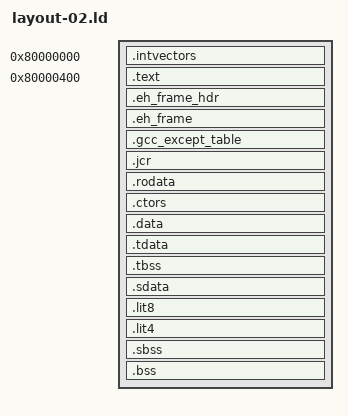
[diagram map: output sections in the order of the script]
/* ========================================================================
 *
 * n64.ld -- Libdragon linker script
 *
 * Originally based on n64ld.x, developed by Frank Somers <frank@g0dev.com>,
 * with modifications by hcs (halleyscometsoftware@hotmail.com),
 * released under the Unlicense.
 * ========================================================================
 */

OUTPUT_FORMAT ("elf32-bigmips", "elf32-bigmips", "elf32-littlemips")
OUTPUT_ARCH (mips)
EXTERN (_start)
ENTRY (_start)

PHDRS
{
    irq PT_LOAD AT ( 0x80000000 );
    main PT_LOAD AT ( 0x80000400 );
}

SECTIONS {
    .intvectors 0x80000000 : {
        . = ALIGN(32);
        KEEP(*(.intvectors))
        __intvectors_end = .;
    } :irq

    /* The text section carries the app code and its relocation addr is
    * the first byte of the cart domain in cached, unmapped memory
    */
    .text 0x80000400 : {
        __text_start = .;
        *(.boot)
        . = ALIGN(16);
        *(.text)
        /* MipsFit: verified unique input sections; GC remains enabled */
        *(.text.sinf_approx)
        *(.text.fm_sincosf)
        *(.text._ZN3e645water6updateEf)
        *(.text._ZN3e6410angle_wrapEf)
        *(.text._ZN3e646player21setCharacter3DControlENS_8PlayerIDEPNS_8ViewportE)
        *(.text._exit)
        *(.text.audio_get_num_buffers)
        *(.text._ZN3e644game5state6updateEv)
        *(.text._ZN3e644mesh6deform6updateEPKPNS_8Entity3DEhh)
        *(.text.rdpq_mode_fog)
        *(.text._ZN3e649collision15dynamicAABBTree9queryAABBEPKNS_15DynamicAABBTreeEPvPFiS5_lENS_4AABBE)
        *(.text.t3d_skeleton_update)
        *(.text.t3d_mat4_to_fixed)
        *(.text.t3d_tri_draw_strip)
        *(.text.t3d_mat4_from_srt)
        *(.text._ZN3e6410quaternion12rotateVectorEPKNS_10QuaternionEPKNS_7Vector3E)
        *(.text._ZN3e648skeleton11getBonePoseEPK11T3DSkeletonsP9fm_vec3_tP9fm_quat_t)
        *(.text.rdpq_text_vprintf)
        *(.text._ZN3e643box7raycastEPKNS_3BoxEPKNS_9TransformEPNS_11RaycastDataE)
        *(.text._ZN3e647matrix37productEPKNS_7Matrix3ES3_)
        *(.text._ZN3e647matrix315transformVectorEPKNS_7Matrix3EPKNS_7Vector3E)
        *(.text._ZN3e649transform19mulVectorTransposedEPKNS_9TransformEPKNS_7Vector3E)
        *(.text._ZN3e647stage2d6createEPKNS0_3DefEPNS_8Entity2DE)
        *(.text._ZN3e649transform9mulVectorEPKNS_9TransformEPKNS_7Vector3E)
        *(.text._ZN9gameStateL15controlGameplayEv)
        *(.text._ZN3e644mesh4cullEPNS_4MeshEPK11T3DViewport)
        *(.text.__rdpq_fixup_write8_syncchange)
        *(.text.bvh_query_node)
        *(.text.t3d_model_bvh_query_frustum)
        *(.text.t3d_mat4_from_srt_euler)
        *(.text.t3d_anim_update)
        *(.text.joybus_get_identifier)
        *(.text._ZN3e647contact6solver10initializeEPNS_7Contact6SolverEPNS_7physics6IslandE)
        *(.text.t3d_mat4_to_fixed_3x4)
        *(.text.t3d_mat4fp_from_srt)
        *(.text._ZN3e647scene3d14updateEntitiesEh)
        *(.text.__rdpq_mode_change_som)
        *(.text._ZN3e647scene3d16setRenderContextEPKNS_7Scene3DEPNS_6Render7ContextEPKNS_8ViewportE)
        *(.text._ZN3e644aabb8overlapsEPKNS_4AABBES3_)
        *(.text.__rdpq_set_mode_fill)
        *(.text._ZN3e647contact7manager15findNewContactsEPNS_7Contact7ManagerE)
        *(.text._ZN3e6411character3dL14weaponModifierEP11T3DSkeletonPv)
        *(.text.t3d_quat_nlerp)
        *(.text.fm_sinf)
        *(.text._ZN3e649particles6updateEh)
        *(.text.__rdpq_block_run_no_rdp)
        *(.text.__vi_interrupt)
        *(.text._ZN3e647capsule11computeAABBEPKNS_7CapsuleEPKNS_9TransformEPNS_4AABBE)
        *(.text._ZN3e647matrix312outerProductEPKNS_7Vector3ES3_)
        *(.text._ZN3e648viewport6attachEv)
        *(.text.joypad_get_buttons_held)
        *(.text._ZN3e6411character2d8movementL10setRollingEPNS_11Character2DEPNS0_15MovementCommandEf)
        *(.text._ZN3e649particles4drawEv)
        *(.text._ZN3e644mesh4part9setOffsetEPNS_4MeshEhPKNS_6Render9TransformE)
        *(.text.t3d_matrix_push)
        *(.text.t3d_matrix_stack)
        *(.text.rdpq_text_printf)
        *(.text.vi_write_masked)
        *(.text._ZN3e644mesh17setMatrixFromBodyEPNS_4MeshEPKNS_7Vector3EPKNS_10QuaternionES5_h)
        *(.text.rspq_block_run)
        *(.text._ZN3e649rigidBody7isAwakeEPKNS_9RigidBodyE)
        *(.text._ZN3e646renderL11runElementsEPKNS_6Render7ContextEPKttPPK11T3DSkeletonPPK9T3DMat4FP.constprop.0)
        *(.text._ZN3e644menu7control4readEPNS0_8ControlsEPKNS_10ControllerEPKNS0_14ControlBindingE)
        *(.text._ZN3e6411character3d9Animation18setLocomotionSpeedERNS_11Character3DEf)
        *(.text._ZN3e649collision15dynamicAABBTreeL10insertLeafEPNS_15DynamicAABBTreeEl)
        *(.text._ZN3e647contact7manager14testCollisionsEPNS_7Contact7ManagerE)
        *(.text._ZN3e644menu7controlL7getStepENS1_9DirectionEbb)
        *(.text._ZN3e649collision11sphereToBoxEPNS_7Contact8ManifoldEPNS_7physics5ShapeES6_)
        *(.text._ZN3e649transform7productEPKNS_9TransformES3_)
        *(.text._ZN3e649rigidBody10canCollideEPKNS_9RigidBodyES3_)
        *(.text.__entropy_add)
        *(.text.mixer_ch_play)
        *(.text.t3d_light_set_ambient)
        *(.text.t3d_segment_set)
        *(.text.acct_switch)
        *(.text._ZN3e649collision8boxToBoxEPNS_7Contact8ManifoldEPNS_7physics5ShapeES6_)
        *(.text._ZN3e644mesh4part9getMatrixEPKNS_4MeshEhh)
        *(.text._ZN3e649collision7collideEPNS_7Contact8ManifoldEPNS_7physics5ShapeES6_)
        *(.text._ZN3e648entity3d12setTransformEPNS_8Entity3DEPKNS_11character3d13KinematicBodyE)
        *(.text._ZN3e648camera3d14getAngleAroundEPKNS_6CameraEPKNS_7Vector3E)
        *(.text.rspq_flush_internal)
        *(.text.joypad_vi_interrupt_callback)
        *(.text._ZN3e6410quaternion7productEPKNS_10QuaternionES3_)
        *(.text.joypad_get_axis_values.constprop.0)
        *(.text.rdpq_fence)
        *(.text.joypad_get_inputs)
        *(.text.__rdpq_interrupt)
        *(.text.__rdpq_clear)
        *(.text.t3d_light_set_count)
        *(.text.t3d_vec3_cross)
        *(.text._ZN3e644time6updateEv)
        *(.text._ZN3e644meshL11composePartEPKNS_4MeshEPKNS_6Render9TransformEPNS_7Vector3EPNS_10QuaternionES9_)
        *(.text.rdpq_detach_cb)
        *(.text.timer_update_compare)
        *(.text.mips_disasm)
        *(.text._ZN3e649collision17capsuleToTriangleEPNS_7Contact8ManifoldEPKNS_7CapsuleEPKNS_9TransformEPKNS_8TriangleE)
        *(.text.display_get_fps)
        *(.text._ZN3e648triangle14closestToPointEPKNS_8TriangleEPKNS_7Vector3E)
        *(.text._ZN3e644time5resetEv)
        *(.text.rdpq_mode_antialias)
        *(.text.timer_callback)
        *(.text._ZN3e643box9testPointEPKNS_3BoxEPKNS_9TransformEPKNS_7Vector3E)
        *(.text._ZN3e647matrix325transformVectorTransposedEPKNS_7Matrix3EPKNS_7Vector3E)
        *(.text._ZN3e6411character2d8movementL13setLocomotionEPNS_11Character2DEPNS0_15MovementCommandEf)
        *(.text.display_set_fps_limit)
        *(.text._ZN3e647contact10constraint14solveCollisionEPNS_7Contact10ConstraintE)
        *(.text._ZN3e648camera3d7controlL17setSpringArmInputEPNS_6CameraEff)
        *(.text.t3d_mat4_to_frustum)
        *(.text._ZN3e648camera3d9springArm6updateEPNS_6CameraEPNS_7Vector3Ef)
        *(.text._ZN3e6410controller3getEv)
        *(.text.rspq_flush)
        *(.text.mixer_try_play)
        *(.text.exception_reset_time)
        *(.text.rdpq_paragraph_builder_span)
        *(.text._ZN3e644aabb12containsAABBEPKNS_4AABBES3_)
        *(.text._ZN3e647vector39normalizeEPNS_7Vector3E)
        *(.text.t3d_mat4_mul_vec3)
        *(.text._ZN3e6410controller6isHeldEPKNS_10ControllerENS_8ButtonIDE)
        *(.text._ZL27staminaWheel_setRenderStatePK12StaminaWheel)
        *(.text.si_interrupt)
        *(.text.rdpq_font_load_buf)
        *(.text._ZN3e646render4drawEv)
        *(.text._ZN3e645debug2ui4drawEv)
        *(.text.vi_write_begin)
        *(.text._ZN3e642ui16setRenderContextEPKNS_2UIEPNS_6Render7ContextE)
        *(.text.t3d_matrix_set_proj)
        *(.text._ZSt14get_unexpectedv)
        *(.text.joypad_get_buttons_pressed)
        *(.text._ZN3e649collision15dynamicAABBTree6updateEPNS_15DynamicAABBTreeElNS_4AABBE)
        *(.text._ZN3e647physics5shape9testPointEPKNS0_5ShapeEPKNS_7Vector3E)
        *(.text.display_get_zbuf)
        *(.text._ZN3e648viewport8getScaleEv)
        *(.text._ZN3e643fog3getEv)
        *(.text.__rdpq_write8_syncchange)
        *(.text.__rdpq_fill_rectangle)
        *(.text.t3d_viewport_set_projection)
        *(.text._ZN3e644time4initEv)
        *(.text.__TI_handler)
        *(.text.audio_get_queued_buffers)
        *(.text.t3d_dmem_set_u16)
        *(.text.rewind_anim)
        *(.text.t3d_dmem_set_u32)
        *(.text._ZN3e643fog3setEPNS_3FogE)
        *(.text._ZN3e6410controller10isReleasedEPKNS_10ControllerENS_8ButtonIDE)
        *(.text.rdpq_detach_show)
        *(.text._ZN3e644mesh8material10isDeferredEh)
        *(.text.fm_cosf)
        *(.text._ZN3e645sound4pollEv)
        *(.text._ZN3e649collision15dynamicAABBTree11getUserDataEPKNS_15DynamicAABBTreeEl)
        *(.text._ZN3e644game7runStepEv)
        *(.text.vi_write_idx_masked)
        *(.text.rdpq_mode_filter)
        *(.text._ZN3e649transform17productTransposedEPKNS_9TransformES3_)
        *(.text.waveform_vadpcm_read_compressed.isra.0)
        *(.text._ZN3e6410quaternion9toMatrix3EPKNS_10QuaternionE)
        *(.text.joypad_read_async.part.0)
        *(.text.display_show)
        *(.text._ZN3e647scene2d3getEv)
        *(.text._ZN3e644mesh6deform9bindFrameEPNS_4MeshEh)
        *(.text.audio_callback.part.0)
        *(.text.vi_show)
        *(.text.rdpq_set_mode_standard)
        *(.text.__vblank_interrupt)
        *(.text._ZN3e646memory5stack8allocateEPNS0_5StackEl)
        *(.text._ZN3e6410controller18getStickNormalizedEPKNS_10ControllerE)
        *(.text.joybus_exec_async)
        *(.text.enable_interrupts)
        *(.text.audio_get_buffer_length)
        *(.text.display_try_get)
        *(.text._ZN3e647matrix37inverseEPKNS_7Matrix3E)
        *(.text._ZN3e649rigidBody18synchronizeProxiesEPNS_9RigidBodyE)
        *(.text._ZN3e647physics5shape11computeAABBEPKNS0_5ShapeEPNS_4AABBE)
        *(.text.vi_write_end)
        *(.text.joypad_get_buttons_released)
        *(.text._ZN3e6416ease_quad_in_outEf)
        *(.text._ZN3e649animation13syncGridClipsEPNS_9AnimationEPKNS1_4NodeEff)
        *(.text._ZN3e649animation12getGridClipsEPKNS_9Animation4NodeEffPh)
        *(.text._ZN3e6412ease_expo_inEf)
        *(.text._ZN3e649collision10broadPhase6updateEPNS_10BroadPhaseElNS_4AABBE)
        *(.text._ZN3e645light3setEPKNS0_3DefE)
        *(.text._ZN3e6410quaternion9fromEulerEfff)
        *(.text._ZN3e6411character3d7physicsL15collectTriangleEPvl)
        *(.text._ZN3e648camera3d7control6updateEPNS_6CameraEPKNS0_14ControlBindingEPKNS_7Scene3DEf)
        *(.text.rdpq_sync_full)
        *(.text._ZN3e6411character3d9Animation13getTurningAvgEPKNS0_17AnimationSettingsEff)
        *(.text.t3d_screen_clear_depth)
        *(.text.attach)
        *(.text._ZN3e6411character3d9Animation12getGaitParamEfPKNS0_16MovementSettingsE)
        *(.text.audio_callback)
        *(.text._ZN3e644game3getEv)
        *(.text._ZN3e649collision10broadPhase11testOverlapEPKNS_10BroadPhaseEll)
        *(.text._ZN3e642ui3getEv)
        *(.text._ZN3e644mesh9setMatrixEPNS_4MeshEPKNS_6Render9TransformEh)
        *(.text.__mixer_round_wait)
        *(.text.texload_recalc_tileparms)
        *(.text.rdpq_text_get_font)
        *(.text.__rdpq_texture_rectangle_offline)
        *(.text.__rdpq_texture_rectangle)
        *(.text.rdpq_font_render_paragraph)
        *(.text.mixer_channel_volumes)
        *(.text._ZN3e6410controllerL10readButtonEPK16joypad_buttons_uNS_8ButtonIDE)
        *(.text.__MI_handler)
        *(.text.data_cache_hit_writeback)
        *(.text._ZN3e647physics6island7addBodyEPNS0_6IslandEPNS_9RigidBodyE)
        *(.text._ZN3e647scene3d16updateCharactersEh)
        *(.text.__retarget_lock_release_recursive)
        *(.text.__rdpq_set_fill_color)
        *(.text.t3d_viewport_look_at)
        *(.text._ZN3e644meshL11writeMatrixEP9T3DMat4FPPKNS_7Vector3EPKNS_10QuaternionES5_)
        *(.text.__rdpq_write8)
        *(.text.joypad_is_connected)
        *(.text.t3d_viewport_set_perspective)
        *(.text._ZN3e6411character2d7physics7collideEPNS_11Character2DE)
        *(.text.joypad_accessory_polled)
        *(.text.startup.__ktls_constructor)
        *(.text._ZN3e646renderL13scrollTextureEPK11T3DMaterialPKNS_7Vector2E)
        *(.text.data_cache_hit_invalidate)
        *(.text._ZN3e649animation7getClipEPNS_9AnimationEh)
        *(.text.rdpq_paragraph_render)
        *(.text._ZN3e647scene3d3getEv)
        *(.text.joypad_detect_callback)
        *(.text._ZN3e6411uiAnimation6player6updateEPNS_11UIAnimation6PlayerEPNS_2UIEf)
        *(.text._ZN3e647scene3d10getPhysicsEv)
        *(.text.__rdpq_fill_rectangle_offline)
        *(.text._ZN3e6410controller19getCStickNormalizedEPKNS_10ControllerE)
        *(.text.__rdpq_fixup_mode3)
        *(.text.decompress_aplib_partial.part.0)
        *(.text.__rdpq_reset_render_mode)
        *(.text._ZN3e647vector312computeBasisEPKNS_7Vector3EPS1_S4_)
        *(.text.kirq_begin_wait_vi)
        *(.text.fm_expf)
        *(.text.get_ticks)
        *(.text.__rdpq_autosync_change)
        *(.text.t3d_vec3_norm)
        *(.text.rdpq_mode_end)
        *(.text.rdpq_mode_push)
        *(.text._ZN3e642ui6updateEPKNS_11UIAnimationE)
        *(.text._ZN3e649rigidBody12getTransformEPKNS_9RigidBodyE)
        *(.text._ZN3e649rigidBody17setLinearVelocityEPNS_9RigidBodyENS_7Vector3E)
        *(.text.mixer_ch_alloc)
        *(.text._ZN3e6411character3d9Animation18setLocomotionParamERNS_11Character3DEf)
        *(.text._ZN3e649animation12blendSegmentEfhPf)
        *(.text.rspq_highpri_end)
        *(.text.__rsp_crash)
        *(.text.t3d_mat4_look_at)
        *(.text._ZN3e6424segment_closestToSegmentEPKNS_7Vector3ES2_S2_S2_PS0_S3_)
        *(.text.rdpq_mode_persp)
        *(.text.__rdpq_fixup_mode4)
        *(.text._ZN3e647contact6solver8shutdownEPNS_7Contact6SolverE)
        *(.text.joybus_msg_send)
        *(.text.rdpq_text_printn)
        *(.text._ZN3e647physics4stepEPNS0_5WorldE)
        *(.text._ZN3e644aabb14closestToPointEPKNS_4AABBEPKNS_7Vector3E)
        *(.text._ZN3e645light3getEv)
        *(.text._ZN3e649collision15dynamicAABBTree10getFatAABBEPKNS_15DynamicAABBTreeEl)
        *(.text._ZN3e6411character3d8movementL13setLocomotionEPNS_11Character3DEPNS0_15MovementCommandEf)
        *(.text._ZN3e647capsule10getSegmentEPKNS_7CapsuleEPKNS_9TransformEPNS_7Vector3ES8_)
        *(.text._ZN3e649rigidBody23setTransformPositionYawEPNS_9RigidBodyENS_7Vector3Ef)
        *(.text._ZN3e6412meshCollider9queryAABBEPKNS_12MeshColliderEPvPFiS4_lENS_4AABBE)
        *(.text._ZN3e649collision10broadPhase11updatePairsEPNS_10BroadPhaseE)
        *(.text._ZN3e649collision22capsuleToStaticCapsuleEPNS_7Contact8ManifoldEPKNS_7CapsuleEPKNS_9TransformES6_S9_)
        *(.text._ZN3e648entity3d17setMatrixFromBodyEPNS_8Entity3DEh)
        *(.text._ZN3e646memory5stack4freeEPNS0_5StackEPv)
        *(.text._ZN3e6410quaternion11toAxisAngleEPKNS_10QuaternionEPNS_7Vector3EPf)
        *(.text._ZN3e6411character3d9Animation11getGaitAxisERKNS_11Character3DEf)
        *(.text._ZN3e6411character3d9Animation9setParamsERNS_11Character3DEf)
        *(.text._ZN3e649animation14setActiveNodesEPNS_9AnimationE)
        *(.text._ZN3e6411character3d9Animation13setJumpParamsERNS_11Character3DEf)
        *(.text._ZN3e645waterL6scrollEPNS_7Vector2EPKfff)
        *(.text.display_get)
        *(.text._ZN3e6411character3d9Animation21setStrafeLockedParamsERNS_11Character3DEf)
        *(.text.display_get_width)
        *(.text._ZN3e6411character3d9Animation12setRollParamERNS_11Character3DEf)
        *(.text.joypad_poll.part.0)
        *(.text._ZN3e6411character3d9Animation19setJumpFootingSpeedERNS_11Character3DE)
        *(.text._ZN3e6411character3d9Animation13setSwimParamsERNS_11Character3DEf)
        *(.text._ZL21staminaWheel_setInputPN3e648ParticleEh)
        *(.text.__rdpq_fixup_mode)
        *(.text.__rdpq_set_color_image)
        *(.text.rdpq_attach)
        *(.text.t3d_mat4_perspective)
        *(.text.joypad_inputs_from_n64_controller_read)
        *(.text.rdpq_set_z_image)
        *(.text.decompress_shrinkler_read)
        *(.text.__retarget_lock_acquire_recursive)
        *(.text._ZN3e6411character3d9Animation15setStrafeParamsERNS_11Character3DEf)
        *(.text._ZN3e649propSound6updateEPNS_7physics5WorldE)
        *(.text.t3d_light_set_point)
        *(.text.internal_open)
        *(.text._ZN3e647physics6island5solveEPNS0_6IslandE)
        *(.text.audio_write_begin)
        *(.text.fm_atan2f)
        *(.text.__rdpq_set_scissor)
        *(.text._ZN3e646player6updateEv)
        *(.text._ZN3e649rigidBody10setToAwakeEPNS_9RigidBodyE)
        *(.text.disable_interrupts)
        *(.text.texload_block_8bpp)
        *(.text.joypad_read_callback)
        *(.text._ZN3e648viewport5clearE7color_t)
        *(.text.__vi_validate_config)
        *(.text.__display_callback)
        *(.text._ZN3e647matrix36scaledEPKNS_7Matrix3Ef)
        *(.text._ZN3e647contact6solver8preSolveEPNS_7Contact6SolverEf)
        *(.text._ZN3e6411character3d8movement7setModeEPNS0_8MovementEh)
        *(.text._ZN3e6411character3d7control6updateEPNS_11Character3DEPNS0_15MovementCommandEPKNS0_8ControlsEf)
        *(.text._ZN3e6411character3d5sound6updateEPNS_11Character3DE)
        *(.text._ZN3e646memory4heap4initEPNS0_4HeapE)
        *(.text.__rdpq_clear_z_with_rsp)
        *(.text._ZN3e6411character3d6weapon5drawnEPKNS_11Character3DE)
        *(.text._ZN3e6411character3d5stats6updateEPNS_11Character3DEPKNS0_15MovementCommandEf)
        *(.text._ZN3e646player3getEv)
        *(.text._ZN3e645sound6updateEv)
        *(.text.usb_initialize)
        *(.text.rdpq_mode_pop)
        *(.text.t3d_viewport_attach)
        *(.text.t3d_matrix_set)
        *(.text.rdpq_paragraph_builder_font)
        *(.text.audio_write_end)
        *(.text.t3d_matrix_pop)
        *(.text._ZN3e644mesh8material11hasVertexFxEh)
        *(.text._ZN3e648camera3d8getRightEPKNS_6CameraE)
        *(.text._ZN3e647contact6solver5solveEPNS_7Contact6SolverE)
        *(.text.decompress_lz4_read)
        *(.text._ZN3e647physics6updateEPNS0_5WorldEf)
        *(.text._ZN3e6411Character3D14updateMovementEPNS_11character3d15MovementCommandEf)
        *(.text._ZN3e6411character3d8movementL21setHorizontalVelocityEPNS_11Character3DEffff)
        *(.text._ZN3e648viewport6detachEv)
        *(.text.joypad_poll)
        *(.text.rdpq_paragraph_builder_end)
        *(.text._ZN3e644mesh8material5blockEh)
        *(.text.rdpq_mode_dithering)
        *(.text.__rdpq_paragraph_builder_update_bbox_width.part.0)
        *(.text._ZN3e648entity3d9setMatrixEPNS_8Entity3DEh)
        *(.text.rspq_highpri_begin)
        *(.text._ZN3e6411character2d9animation6updateEPNS_11Character2DEf)
        *(.text._ZN9gameStateL14updateGameplayEv)
        *(.text._ZN3e649collision10broadPhase11insertShapeEPNS_10BroadPhaseEPNS_7physics5ShapeENS_4AABBE)
        *(.text.vi_set_origin)
        *(.text._ZN3e6411character3d9Animation10setFootingERNS_11Character3DE)
        *(.text._ZN3e6411character3d7physics7collideEPNS_11Character3DEPKNS_7physics5WorldE)
        *(.text.mixer_poll_async)
        *(.text.mixer_emit_channel)
        *(.text.__rdpq_paragraph_build)
        *(.text.vi_get_refresh_rate)
        *(.text.rdpq_mode_begin)
        *(.text._ZN3e646memory5stack7reserveEPNS0_5StackEm)
        *(.text.kmutex_lock)
        *(.text.rspq_switch_context)
        *(.text.rdpq_paragraph_builder_begin)
        *(.text._ZN3e6411character3d6createEPKNS0_3DefEPNS_8Entity3DE)
        *(.text._ZN3e6411character3d9Animation14setClimbParamsERNS_11Character3DEf)
        *(.text.graphics_draw_box)
        *(.text._ZN3e647vector310normalizedEPKNS_7Vector3E)
        *(.text._ZN3e6411ease_linearEf)
        *(.text._ZN3e6411character3d9Animation15setAimingParamsERNS_11Character3DEf)
        *(.text._ZN3e647scene2d4loadEPKNS0_3DefEPKNS_8controls3DefE)
        *(.text.rdpq_set_color_image)
        *(.text._ZN3e648camera3d6updateEPNS_6CameraEPNS_7Vector3EPKNS_7Scene3DEf)
        *(.text._ZN3e645debug2ui7showFPSEv)
        *(.text.rspq_next_buffer)
        *(.text._ZN3e648viewport5has3DEv)
        *(.text._ZN3e6411character3d7physics8syncBodyEPNS_11Character3DE)
        *(.text._ZN3e646memory4heap8allocateEPNS0_4HeapEl)
        *(.text._ZN3e648buoyancy5applyEPNS_7physics5WorldEPKNS0_6VolumeE)
        *(.text.__rdpq_clear_z)
        *(.text._ZN3e647physics6island10initializeEPNS0_6IslandE)
        *(.text._ZN3e647scene2d16setRenderContextEPKNS_7Scene2DEPNS_6Render7ContextE)
        *(.text._ZN3e6411character3d3aim5applyEP11T3DSkeletonPv)
        *(.text._ZN3e6411character3d7control4readEPNS0_8ControlsEPKNS0_14ControlBindingE)
        *(.text._ZNSt9type_infoD2Ev)
        *(.text.t3d_frustum_vs_aabb_s16)
        *(.text.joybus_identify_callback)
        *(.text._ZN3e6411character3d8movement12isLocomotionEh)
        *(.text._ZN3e648viewport20setPerspectiveCameraEv)
        *(.text._ZN3e6410controller4pollEv)
        *(.text.t3d_mat4_mul)
        *(.text.timer_poll)
        *(.text.__rspq_deferred_poll)
        *(.text.joybus_identify_async.part.0)
        *(.text.inspector_stdout)
        *(.text._ZN3e644meshL12localFrustumEP10T3DFrustumPKS1_PKNS_7Vector3EPKNS_10QuaternionES7_)
        *(.text._ZN3e6410quaternion13fromAxisAngleEPKNS_7Vector3Ef)
        *(.text._ZN3e6411character3d7physicsL19floorProbe_considerEPNS1_10FloorProbeEPKNS_7Vector3EfS6_.isra.0)
        *(.text.mixer_ch_seek)
        *(.text.__cxa_get_globals_fast)
        *(.text._ZN3e648skeleton9modifiers5applyEPNS0_9ModifiersEP11T3DSkeleton)
        *(.text._ZN3e6410controller9isPressedEPKNS_10ControllerENS_8ButtonIDE)
        *(.text.t3d_frame_start)
        *(.text._ZN3e647vector39magnitudeEPKNS_7Vector3E)
        *(.text.startup.main)
        *(.text._ZN3e6411Character3D12setAnimationEv)
        *(.text.__rdpq_font_glyph)
        *(.text._ZN3e64L33springBoneCollision_collideSphereEPKNS_7Vector3EfbffS2_.isra.0)
        *(.text._ZN3e6416springBone_applyEP11T3DSkeletonPv)
        *(.text._ZN3e6410quaternion11fromMatrix3EPKNS_7Matrix3E)
        *(.text._ZN3e649animation8evaluateEPNS_9AnimationEf)
        *(.text.startup.__init_cop1)
        *(.text._ZN3e649animation6buffer11blendLayersEPKNS_9Animation6BufferEPK11T3DSkeleton)
        *(.text._ZN3e649animation14closeIdleClipsEPNS_9AnimationE)
        *(.text._ZNKSt9type_info14__is_pointer_pEv)
        *(.text._ZN3e644time3getEv)
        *(.text.joypad_get_axis_pressed)
        *(.text.__rdpq_block_run_with_rdp)
        *(.text._ZN3e6411character3d6weapon8setBonesEPNS_11Character3DE)
        *(.text._ZN3e649collision15dynamicAABBTree6insertEPNS_15DynamicAABBTreeENS_4AABBEPv)
        *(.text._ZN3e649collision18capsuleToStaticBoxEPNS_7Contact8ManifoldEPKNS_7CapsuleEPKNS_9TransformEPKNS_3BoxES9_)
        *(.text._ZN3e6411character3d7physicsL7recoverEPNS_11Character3DEPKNS_7physics5WorldEPNS1_14CollisionStateE.constprop.0)
        *(.text._ZN3e644aabb16closestToSegmentEPKNS_4AABBEPKNS_7Vector3ES6_)
        *(.text._ZN3e6422segment_closestToPointEPKNS_7Vector3ES2_S2_)
        *(.text.rspq_overlay_register_static)
        *(.text._ZN3e6412meshCollider11getTriangleEPKNS_12MeshColliderElPNS_8TriangleE)
        *(.text._ZN3e6416ease_expo_in_outEf)
        *(.text._ZN3e649particles6buffer6createENS_8Particle4TypeEm)
        *(.text.rdpq_tex_blit)
        *(.text._ZN3e644menu8getIndexEv)
        *(.text._ZN3e647physics5world7setWindEPNS0_5WorldENS_7Vector3E)
        *(.text._ZN3e649collision17fixTriangleNormalEPKNS_8TriangleEPKNS_7Vector3ES6_S6_)
        *(.text.backtrace_foreach.constprop.0)
        *(.text.__mixer_rdram_copy)
        *(.text._ZN3e6411character3d7physicsL13floorDistanceEPKNS_11Character3DEPKNS_7physics5WorldE)
        *(.text.ioctl)
        *(.text._ZN3e649rigidBody8addShapeEPNS_9RigidBodyEPKNS_7physics5Shape3DefENS_7Vector3E)
        *(.text.joybus_detect_now)
        *(.text.tpx_particle_draw_s8)
        *(.text._ZN3e645cloth4stepEPNS_5ClothEf)
        *(.text._ZN3e648viewport3getEv)
        *(.text._ZN3e6419angle_wrap_relativeEff)
        *(.text._ZN3e6412ease_quad_inEf)
        *(.text._ZN3e6413ease_quad_outEf)
        *(.text._ZN3e6413ease_cubic_inEf)
        *(.text._ZN3e6414ease_cubic_outEf)
        *(.text._ZN3e6417ease_cubic_in_outEf)
        *(.text._ZN3e6413ease_expo_outEf)
        *(.text._ZN3e647matrix38diagonalEfff)
        *(.text._ZN3e647matrix310differenceEPKNS_7Matrix3ES3_)
        *(.text._ZN3e647matrix37setRowsEPNS_7Matrix3EPKNS_7Vector3ES5_S5_)
        *(.text._ZN3e647matrix33sumEPKNS_7Matrix3ES3_)
        *(.text._ZN3e6410quaternion8identityEv)
        *(.text._ZN3e6410quaternion10normalizedEPKNS_10QuaternionE)
        *(.text._ZN3e6410quaternion9integrateEPNS_10QuaternionEPKNS_7Vector3Ef)
        *(.text._ZN3e647vector29magnitudeEPKNS_7Vector2E)
        *(.text._ZN3e646memory4heap8shutdownEPNS0_4HeapE)
        *(.text._ZN3e646memory4heap4freeEPNS0_4HeapEPv)
        *(.text._ZN3e646memory5paged4initEPNS0_14PagedAllocatorEll)
        *(.text._ZN3e646memory5paged8shutdownEPNS0_14PagedAllocatorE)
        *(.text._ZN3e646memory5paged8allocateEPNS0_14PagedAllocatorE)
        *(.text._ZN3e646memory5paged4freeEPNS0_14PagedAllocatorEPv)
        *(.text._ZN3e646memory5stack4initEPNS0_5StackE)
        *(.text._ZN3e646memory5stack8shutdownEPNS0_5StackE)
        *(.text._ZN3e644aabb11surfaceAreaEPKNS_4AABBE)
        *(.text._ZN3e644aabb7combineEPKNS_4AABBES3_)
        *(.text._ZN3e647raycast3setEPNS_11RaycastDataEPKNS_7Vector3ES5_f)
        *(.text._ZN3e648triangle7raycastEPKNS_8TriangleEPNS_11RaycastDataE)
        *(.text._ZN3e643box11computeAABBEPKNS_3BoxEPKNS_9TransformEPNS_4AABBE)
        *(.text._ZN3e643box11computeMassEPKNS_3BoxEPKNS_9TransformEfPNS_7physics5shape8MassDataE)
        *(.text._ZN3e647capsule9testPointEPKNS_7CapsuleEPKNS_9TransformEPKNS_7Vector3E)
        *(.text._ZN3e647capsule7raycastEPKNS_7CapsuleEPKNS_9TransformEPNS_11RaycastDataE)
        *(.text._ZN3e647capsule11computeMassEPKNS_7CapsuleEPKNS_9TransformEfPNS_7physics5shape8MassDataE)
        *(.text._ZN3e647physics5shape3def14localTransformEPKNS_9TransformE)
        *(.text._ZN3e647physics5shape7fromDefEPNS0_5ShapeEPKNS2_3DefENS_7Vector3E)
        *(.text._ZN3e647physics5shape7releaseEPNS0_5ShapeE)
        *(.text._ZN3e647physics5shape7raycastEPKNS0_5ShapeEPNS_11RaycastDataE)
        *(.text._ZN3e647physics5shape11computeMassEPKNS0_5ShapeEPNS1_8MassDataE)
        *(.text._ZN3e646sphere9testPointEPKNS_6SphereEPKNS_9TransformEPKNS_7Vector3E)
        *(.text._ZN3e646sphere7raycastEPKNS_6SphereEPKNS_9TransformEPNS_11RaycastDataE)
        *(.text._ZN3e646sphere11computeAABBEPKNS_6SphereEPKNS_9TransformEPNS_4AABBE)
        *(.text._ZN3e646sphere11computeMassEPKNS_6SphereEPKNS_9TransformEfPNS_7physics5shape8MassDataE)
        *(.text._ZN3e649collision10broadPhase12treeCallbackEPvl)
        *(.text._ZN3e649collision10broadPhaseL8pair_cmpEPKvS3_)
        *(.text._ZN3e649collision10broadPhase4initEPNS_10BroadPhaseEPNS_7Contact7ManagerE)
        *(.text._ZN3e649collision10broadPhase8shutdownEPNS_10BroadPhaseE)
        *(.text._ZN3e649collision10broadPhase11removeShapeEPNS_10BroadPhaseEPKNS_7physics5ShapeE)
        *(.text._ZN3e649collisionL12orthographicEffllPNS0_10ClipVertexElS2_)
        *(.text._ZN3e649collisionL13trackEdgeAxisEPllfPfNS_7Vector3EPS3_)
        *(.text._ZN3e649collisionL11supportEdgeENS_9TransformENS_7Vector3ES2_PS2_S3_)
        *(.text._ZN3e649collisionL15collectTriangleEPvl)
        *(.text._ZN3e649collision14sphereToSphereEPNS_7Contact8ManifoldEPNS_7physics5ShapeES6_)
        *(.text._ZN3e649collision12capsuleToBoxEPNS_7Contact8ManifoldEPNS_7physics5ShapeES6_)
        *(.text._ZN3e649collision15sphereToCapsuleEPNS_7Contact8ManifoldEPNS_7physics5ShapeES6_)
        *(.text._ZN3e649collision16capsuleToCapsuleEPNS_7Contact8ManifoldEPNS_7physics5ShapeES6_)
        *(.text._ZN3e649collision21capsuleToStaticSphereEPNS_7Contact8ManifoldEPKNS_7CapsuleEPKNS_9TransformEPKNS_6SphereES9_)
        *(.text._ZN3e649collisionL11shapeToMeshEPNS_7Contact8ManifoldEPNS_7physics5ShapeES6_)
        *(.text._ZN3e647contact8manifold7setPairEPNS_7Contact8ManifoldEPNS_7physics5ShapeES7_)
        *(.text._ZN3e647contact7manager4initEPNS_7Contact7ManagerEPNS_6memory5StackE)
        *(.text._ZN3e647contact7manager8shutdownEPNS_7Contact7ManagerE)
        *(.text._ZN3e647contact7manager10addContactEPNS_7Contact7ManagerEPNS_7physics5ShapeES7_)
        *(.text._ZN3e647contact7manager13removeContactEPNS_7Contact7ManagerEPNS2_10ConstraintE)
        *(.text._ZN3e647contact7manager22removeContactsFromBodyEPNS_7Contact7ManagerEPNS_9RigidBodyE)
        *(.text._ZN3e649collision15dynamicAABBTreeL12allocateNodeEPNS_15DynamicAABBTreeE)
        *(.text._ZN3e649collision15dynamicAABBTreeL13syncHierarchyEPNS_15DynamicAABBTreeEl)
        *(.text._ZN3e649collision15dynamicAABBTreeL14deallocateNodeEPNS_15DynamicAABBTreeEl.part.0)
        *(.text._ZN3e649collision15dynamicAABBTreeL10removeLeafEPNS_15DynamicAABBTreeEl)
        *(.text._ZN3e649collision15dynamicAABBTree4initEPNS_15DynamicAABBTreeE)
        *(.text._ZN3e649collision15dynamicAABBTree8shutdownEPNS_15DynamicAABBTreeE)
        *(.text._ZN3e649collision15dynamicAABBTree6removeEPNS_15DynamicAABBTreeEl)
        *(.text._ZN3e649collision15dynamicAABBTree8queryRayEPKNS_15DynamicAABBTreeEPvPFiS5_lEPNS_11RaycastDataE)
        *(.text._ZN3e6412meshCollider7destroyEPNS_12MeshColliderE)
        *(.text._ZN3e6412meshCollider4loadEPKc)
        *(.text._ZN3e6412meshColliderL11raycastLeafEPvl)
        *(.text._ZN3e6412meshCollider7raycastEPKNS_12MeshColliderEPKNS_9TransformEPNS_11RaycastDataE)
        *(.text._ZN3e648buoyancyL9addSampleEPNS0_5AccumEPKNS0_6VolumeEPKNS_7Vector3ES8_S8_ff)
        *(.text._ZN3e645clothL13updateNormalsEPNS_5ClothE.part.0)
        *(.text._ZN3e645cloth8isCulledEPKNS_5ClothE)
        *(.text._ZN3e645cloth16blendRenderStateEPNS_5ClothEf)
        *(.text._ZN3e645cloth7destroyEPNS_5ClothE)
        *(.text._ZN3e645cloth6createEPNS_5ClothEPKNS_12MeshColliderEPKNS1_3DefE)
        *(.text._ZN3e647physics6island10addContactEPNS0_6IslandEPNS_7Contact10ConstraintE)
        *(.text._ZN3e647physics5world10allocShapeEPNS0_5WorldEPPNS0_5ShapeE)
        *(.text._ZN3e647physics5world9freeShapeEPNS0_5WorldEPNS0_5ShapeE)
        *(.text._ZN3e647physics5world12markNewShapeEPNS0_5WorldE)
        *(.text._ZN3e647physics5world4initEPNS0_5WorldEfNS_7Vector3El)
        *(.text._ZN3e647physics5world11createClothEPNS0_5WorldEPKNS_5Cloth3DefE)
        *(.text._ZN3e647physics5world8shutdownEPNS0_5WorldE)
        *(.text._ZN3e647physics5world10createBodyEPNS0_5WorldEPKNS_9RigidBody3DefE)
        *(.text._ZN3e647physics5world11addBuoyancyEPNS0_5WorldEPKNS_8buoyancy6VolumeE)
        *(.text._ZN3e649rigidBody3def4initEPNS_9RigidBody3DefE)
        *(.text._ZN3e649rigidBody4initEPNS_9RigidBodyEPKNS1_3DefEPNS_7physics5WorldE)
        *(.text._ZN3e649rigidBody15removeAllShapesEPNS_9RigidBodyE)
        *(.text._ZN3e649rigidBody16applyLinearForceEPNS_9RigidBodyENS_7Vector3E)
        *(.text._ZN3e649rigidBody11applyTorqueEPNS_9RigidBodyENS_7Vector3E)
        *(.text._ZN3e649rigidBody10setToSleepEPNS_9RigidBodyE)
        *(.text._ZN3e649rigidBody17calculateMassDataEPNS_9RigidBodyE)
        *(.text._ZN3e649rigidBodyL11attachShapeEPNS_9RigidBodyEPNS_7physics5ShapeEPKNS_9TransformEfffi)
        *(.text._ZN3e649rigidBody10addCapsuleEPNS_9RigidBodyEPKNS_7Capsule3DefE)
        *(.text._ZN3e6411character3d7destroyEPNS_11Character3DE)
        *(.text._ZN3e6411character3d3aim4initEPNS_11Character3DEPKNS0_14AimingSettingsE)
        *(.text._ZN3e6411character3d9Animation24getLockedDirectionWeightERKNS_11Character3DEh)
        *(.text._ZN3e6411character3d9Animation22snapLocomotionFromGridEhf)
        *(.text._ZN3e6411character3d9Animation16setGridRowSpeedsEPKNS_9Animation4NodeE)
        *(.text._ZN3e6411character3d9Animation18getLocomotionPhaseEPKNS0_17AnimationSettingsEff)
        *(.text._ZN3e6411character3d9Animation24getStrafeDirectionWeightERKNS_11Character3DEf)
        *(.text._ZN3e6411character3d9Animation15snapStrafeEntryEv)
        *(.text._ZN3e6411character3d9Animation14snapStrafeExitEv)
        *(.text._ZN3e6411character3d9Animation14syncLandToJumpEv)
        *(.text._ZN3e6411character3d9Animation10snapToJumpEv)
        *(.text._ZN3e6411character3d9Animation10snapToLandEv)
        *(.text._ZN3e6411character3d9Animation10snapToFallEv)
        *(.text._ZN3e6411character3d9Animation20snapRollToLocomotionEb)
        *(.text._ZN3e6411character3d9Animation12setSwimSpeedEPKNS_9Animation4NodeEf)
        *(.text._ZN3e6411character3d9Animation4initEPK8T3DModel)
        *(.text._ZN3e6411character3d9Animation7destroyEv)
        *(.text._ZN3e6411character3d8movementL11setClimbingEPNS_11Character3DEPNS0_15MovementCommandEf)
        *(.text._ZN3e6411character3d8movementL11setSwimmingEPNS_11Character3DEPNS0_15MovementCommandEf)
        *(.text._ZN3e6411character3d8movementL10setRollingEPNS_11Character3DEPNS0_15MovementCommandEf)
        *(.text._ZN3e6411character3d8movementL10setFallingEPNS_11Character3DEPNS0_15MovementCommandEf)
        *(.text._ZN3e6411character3d8movement12isCoyoteOpenEPKNS_11Character3DE)
        *(.text._ZN3e6411character3d8movement14isChargingJumpEPKNS_11Character3DE)
        *(.text._ZN3e6411character3d8collider4initEPNS0_8ColliderEff)
        *(.text._ZN3e6411character3d8collider11setVerticalEPNS0_8ColliderEPKNS_7Vector3E)
        *(.text._ZN3e6411character3d7physics10createBodyEPNS_11Character3DEPNS_7physics5WorldE)
        *(.text._ZN3e6424springBones_resolveChainEPK11T3DSkeletonPKNS_14SpringBonesDefEPsh)
        *(.text._ZN3e6415springBone_initEPNS_10SpringBoneEPK11T3DSkeletonshPKNS_14SpringBonesDefEPKNS_6Render9TransformE)
        *(.text._ZN3e6411character3d6weapon5equipEPNS_11Character3DEhPKNS0_9WeaponDefE)
        *(.text._ZN3e6411character3d6weapon5cycleEPNS_11Character3DEa)
        *(.text._ZN3e648entity2d6createEPKNS0_3DefE)
        *(.text._ZN3e648entity2d7destroyEPNS_8Entity2DE)
        *(.text._ZN3e648entity3d6createEPKNS0_3DefE)
        *(.text._ZN3e648entity3d7destroyEPNS_8Entity3DE)
        *(.text._ZN3e648entity3d9playSoundEPKNS_8Entity3DEhPKNS_7Vector3Ef)
        *(.text._ZN3e648entity3d17colliderTransformEPKNS0_3DefE)
        *(.text._ZN3e648entity3d13attachPhysicsEPNS_8Entity3DEPKNS0_3DefEPNS_7physics5WorldE)
        *(.text._ZN3e646player4initEv)
        *(.text._ZN3e646player14setCharacter3DEPNS_11Character3DEPKNS_11character3d14ControlBindingE)
        *(.text._ZN3e646player14setCharacter2DEPNS_11Character2DEPKNS_11character2d14ControlBindingE)
        *(.text._ZN3e646player17switchCharacter3DENS_8PlayerIDEa)
        *(.text._ZN3e646player21setCharacter2DControlENS_8PlayerIDE)
        *(.text._ZN3e6410controller5startEv)
        *(.text._ZN3e649animation6buffer8addLayerEPNS_9Animation6BufferEPK11T3DSkeletonf.part.0)
        *(.text._ZN3e649animation16snapGridFromClipEPNS_9AnimationEhh)
        *(.text._ZN3e649animation16snapGridFromGridEPNS_9AnimationEhfh)
        *(.text._ZN3e649animation4initEPNS_9AnimationEPKNS1_3DefEPK8T3DModel)
        *(.text._ZN3e649animation7destroyEPNS_9AnimationE)
        *(.text._ZN3e644mesh8materialL13textureEqualsEPK18T3DMaterialTextureS4_)
        *(.text._ZN3e644mesh8material7acquireEPK11T3DMaterial.part.0)
        *(.text._ZN3e644meshL15setPartMatricesEPNS_4MeshEh.part.0)
        *(.text._ZN3e644mesh8material7releaseEh)
        *(.text._ZN3e644mesh10initBoundsEPNS_4MeshE)
        *(.text._ZN3e644mesh14recordGeometryEPNS_4MeshE)
        *(.text._ZN3e644mesh6recordEPNS_4MeshEPKPKchPK9T3DMat4FP)
        *(.text._ZN3e644mesh7releaseEPNS_4MeshE)
        *(.text._ZN3e644mesh4part4findEPKNS_4MeshEPKc)
        *(.text._ZN3e644mesh4part10setVisibleEPNS_4MeshEhb)
        *(.text._ZN3e644mesh6deform3setEPNS_4MeshEPKNS_7Vector3ES6_PKhtf)
        *(.text._ZN3e644mesh6deform7destroyEPNS_4MeshE)
        *(.text._ZN3e648skeleton9modifiers3addEPNS0_9ModifiersEPFvP11T3DSkeletonPvES6_)
        *(.text._ZN3e644font4initEPKNS_4Font3DefEh)
        *(.text._ZN3e644font9loadAssetEh)
        *(.text._ZN3e644font11unloadAssetEh)
        *(.text._ZN3e644text4drawEPKNS_4TextENS_7Vector2E)
        *(.text._ZN3e649rectangle4drawEPKNS_9RectangleENS_7Vector2ES4_)
        *(.text._ZN3e646sprite10isLoadableEPKNS_6SpriteEf)
        *(.text._ZN3e646sprite11loadTextureEPKNS_6SpriteE)
        *(.text._ZN3e646sprite10drawLoadedEPKNS_6SpriteENS_7Vector2ES4_)
        *(.text._ZN3e646sprite9drawTiledEPKNS_6SpriteENS_7Vector2ES4_)
        *(.text._ZN3e646sprite4drawEPKNS_6SpriteENS_7Vector2ES4_f)
        *(.text._ZN3e645water6createEPKNS_5Water3DefE)
        *(.text._ZN3e645water16getSurfaceHeightEPKNS_5WaterEff)
        *(.text._ZN3e645waterL19volumeSurfaceHeightEPKvff)
        *(.text._ZN3e645water11bindPhysicsEPNS_5WaterEPNS_9RigidBodyEPNS_7physics5WorldE)
        *(.text._ZN3e645water15getBoundSurfaceEPKNS_9RigidBodyE)
        *(.text._ZN3e645water5clearEv)
        *(.text._ZN3e646render9transform4initEPNS_6Render9TransformE)
        *(.text._ZN3e643fog4initEPKNS0_3DefE)
        *(.text._ZN3e645light4initEPKNS0_3DefE)
        *(.text._ZN3e647scene3d4loadEPKNS0_3DefEPKNS_8controls3DefE)
        *(.text._ZN3e647scene3d6unloadEv)
        *(.text._ZN3e648camera2dL9setLimitsEPNS_8Camera2DEPNS_7Vector2E.part.0)
        *(.text._ZN3e648camera2d7setZoomEPNS_8Camera2DEf)
        *(.text._ZN3e648camera2d4initEPNS_8Camera2DEPKNS0_3DefE)
        *(.text._ZN3e648camera2d6updateEPNS_8Camera2DENS_7Vector2Eff)
        *(.text._ZN3e648camera2d8toScreenEPKNS_8Camera2DENS_7Vector2Ef)
        *(.text._ZN3e648camera3d4initEPNS_6CameraE)
        *(.text._ZN3e648camera3d5resetEPNS_6CameraE)
        *(.text._ZN3e648camera3d13setViewTargetEPNS_6CameraEPKNS_7Vector3Ef)
        *(.text._ZN3e648camera3d9springArm8getPitchEPKNS_6CameraE)
        *(.text._ZN3e648camera3d9springArm6getYawEPKNS_6CameraE)
        *(.text._ZN3e648camera3d9springArm4initEPNS_6CameraEPKNS0_12SpringArmDefE)
        *(.text._ZN3e648viewportL9applyModeEv)
        *(.text._ZN3e648viewport4initEv)
        *(.text._ZN3e648viewport6open3DEv)
        *(.text._ZN3e648viewport7close3DEv)
        *(.text._ZN3e648viewport7setModeEPKNS_8Viewport7ModeDefE)
        *(.text._ZN3e649particles6bufferL14drawWithMatrixEPKNS_8Particle6BufferEPK9T3DMat4FPb)
        *(.text._ZN3e649particles4initEv)
        *(.text._ZN3e649particles3addEPKNS_8ParticleE)
        *(.text._ZN3e649particles6buffer9setMatrixEPNS_8Particle6BufferEPKfS6_S6_h)
        *(.text._ZN3e645soundL7panningEPKNS_5Sound3DefEPKNS_7Vector3Ef.part.0.isra.0)
        *(.text._ZN3e645soundL12startEmitterEPNS0_12EmitterStateEff)
        *(.text._ZN3e645sound4initEv)
        *(.text._ZN3e645sound4loadEPKNS_5Sound3DefE)
        *(.text._ZN3e645sound6unloadEPNS_5SoundE)
        *(.text._ZN3e645sound4playEPKNS_5SoundEPKNS_7Vector3Eff)
        *(.text._ZN3e645sound15setListenerModeENS_5Sound12ListenerModeE)
        *(.text._ZN3e644game4initEv)
        *(.text._ZN3e644game5state3getEh.part.0)
        *(.text._ZN3e644game5stateL6unloadEh)
        *(.text._ZN3e644game5stateL4loadEh)
        *(.text._ZN3e644game5state3setEh)
        *(.text._ZN3e644game5state5startEPKNS_4Game5State3DefEhh)
        *(.text._ZN3e647scene2d6unloadEv)
        *(.text._ZN3e647scene2d16updateCharactersEf)
        *(.text._ZN3e647scene2d12updateCameraEPKNS_11Character2DEf)
        *(.text._ZN3e647scene2d14getCharacter2DEh)
        *(.text._ZN3e647stage2d7destroyEPNS_7Stage2DE)
        *(.text._ZN3e647stage2d16setRenderContextEPKNS_7Stage2DEPKNS_8Camera2DEPNS_6Render7ContextE)
        *(.text._ZN3e647stage2d7isSolidEPKNS_7Stage2DEll)
        *(.text._ZN3e6411character2dL9setEntityEPNS_11Character2DE)
        *(.text._ZN3e6411character2d6createEPKNS0_3DefEPNS_8Entity2DE)
        *(.text._ZN3e6411character2d7destroyEPNS_11Character2DE)
        *(.text._ZN3e6411character2d6updateEPNS_11Character2DEf)
        *(.text._ZN3e6411character2d9animation4initEPNS_11Character2DEPKNS0_12AnimationDefE)
        *(.text._ZN3e6411character2d9animation4freeEPNS_11Character2DE)
        *(.text._ZN3e6411character2d9animation9getSpriteEPKNS_11Character2DE)
        *(.text._ZN3e6411character2d7control4readEPNS0_8ControlsEPKNS0_14ControlBindingE)
        *(.text._ZN3e6411character2d7control6updateEPNS_11Character2DEPNS0_15MovementCommandEPKNS0_8ControlsE)
        *(.text._ZN3e6411character2d8movementL10setFallingEPNS_11Character2DEPNS0_15MovementCommandEf)
        *(.text._ZN3e6411character2d8movement7setModeEPNS0_8MovementEh)
        *(.text._ZN3e6411character2d8movement12isLocomotionEh)
        *(.text._ZN3e6411character2d8movement12isCoyoteOpenEPKNS_11Character2DE)
        *(.text._ZN3e6411character2d8movement14isChargingJumpEPKNS_11Character2DE)
        *(.text._ZN3e6411Character2D14updateMovementEPNS_11character2d15MovementCommandEf)
        *(.text._ZN3e6411character2d7physicsL9cellRangeEPKNS_7Stage2DEffffPlS5_S5_S5_.isra.0)
        *(.text._ZN3e642ui6unloadEv)
        *(.text._ZN3e642ui4loadEPKNS0_3DefE)
        *(.text._ZN3e642ui9getWidgetEPNS_2UIEhh)
        *(.text._ZN3e642ui4playEPKNS_11UIAnimationEb)
        *(.text._ZN3e642ui15isTransitioningEv)
        *(.text._ZN3e6411uiAnimationL5fieldEPNS_2UIEPKNS_11UIAnimation5TrackE)
        *(.text._ZN3e6411uiAnimationL10applyTrackEPNS_2UIEPKNS_11UIAnimation5TrackEf)
        *(.text._ZN3e6411uiAnimation6playerL10applyFrameEPNS_11UIAnimation6PlayerEPNS_2UIEf.isra.0)
        *(.text._ZN3e6411uiAnimation5applyEPNS_2UIEPKNS_11UIAnimationEf)
        *(.text._ZN3e6411uiAnimation6player5startEPNS_11UIAnimation6PlayerEPNS_2UIEPKS2_NS2_8PlayModeEb)
        *(.text._ZN3e644menu8setIndexEa)
        *(.text._ZN3e644menu9moveIndexEaa)
        *(.text._ZN3e644menu4initEv)
        *(.text._ZN3e648settings3getEv)
        *(.text._ZN3e648settings4initEv)
        *(.text._ZN3e648resource4loadEPKcNS_8Resource4TypeEPKv)
        *(.text._ZN3e648resource6unloadEPv)
        *(.text._ZN3e645debug2ui4initEv)
        *(.text._ZN9gameStateL14updateGameOverEv)
        *(.text._ZN9gameStateL8canLeaveEv)
        *(.text._ZN9gameStateL15enterGameplay2DEv)
        *(.text._ZN9gameStateL13enterMainMenuEv)
        *(.text._ZN9gameStateL10enterIntroEv)
        *(.text._ZN9gameStateL10enterPauseEv)
        *(.text._ZN9gameStateL12controlPauseEv)
        *(.text._ZN9gameStateL11updatePauseEv)
        *(.text._ZN9gameStateL14updateMainMenuEv)
        *(.text._ZN9gameStateL11updateIntroEv)
        *(.text._ZN9gameStateL16updateGameplay2DEv)
        *(.text._ZN9gameStateL12exitGameplayEv)
        *(.text._ZN9gameStateL13enterGameplayEv)
        *(.text._ZN9gameStateL14controlCreditsEv)
        *(.text._ZN9gameStateL12enterCreditsEv)
        *(.text._ZN9gameStateL13updateCreditsEv)
        *(.text._ZN9gameStateL15controlMainMenuEv)
        *(.text._ZN9gameStateL17controlGameplay2DEv)
        *(.text._Z28credits_ui_setScrollVelocityf)
        *(.text._Z22credits_ui_resetScrollv)
        *(.text._Z23credits_ui_updateScrollf)
        *(.text._ZL28staminaWheel_setRenderStateBv)
        *(.text._ZL28staminaWheel_setRenderStateAv)
        *(.text._Z18stamina_wheel_loadv)
        *(.text._Z20stamina_wheel_unloadv)
        *(.text._Z18stamina_wheel_initv)
        *(.text.t3d_mat4fp_from_srt_euler)
        *(.text.t3d_tri_draw_sequence)
        *(.text.t3d_tri_draw_strip_generic)
        *(.text.t3d_init)
        *(.text.t3d_destroy)
        *(.text.t3d_vert_load)
        *(.text.t3d_light_set_directional)
        *(.text.t3d_state_set_drawflags)
        *(.text.t3d_state_set_vertex_fx)
        *(.text.t3d_tri_draw)
        *(.text.t3d_tri_draw_unindexed)
        *(.text.t3d_tri_draw_strip_and_sync)
        *(.text.t3d_fog_set_range)
        *(.text.t3d_viewport_get)
        *(.text.t3d_indexbuffer_convert)
        *(.text.set_texture)
        *(.text.texture_cache_free)
        *(.text.t3d_model_load)
        *(.text.t3d_model_make_object_vert_placeholder)
        *(.text.t3d_model_draw_object)
        *(.text.t3d_model_draw_material)
        *(.text.t3d_model_free)
        *(.text.t3d_model_get_animation)
        *(.text.t3d_model_iter_next)
        *(.text.t3d_skeleton_clone)
        *(.text.t3d_skeleton_reset)
        *(.text.t3d_skeleton_create_buffered)
        *(.text.t3d_skeleton_find_bone)
        *(.text.t3d_skeleton_destroy)
        *(.text.t3d_anim_create)
        *(.text.t3d_anim_attach)
        *(.text.t3d_anim_destroy)
        *(.text.t3d_anim_set_time)
        *(.text.tpx_dmem_set_u32)
        *(.text.tpx_matrix_stack)
        *(.text.tpx_particle_draw_generic_s8)
        *(.text.tpx_particle_draw_generic_s16)
        *(.text.tpx_state_from_t3d)
        *(.text.tpx_state_set_scale)
        *(.text.tpx_state_set_tex_params)
        *(.text.tpx_particle_draw_s16)
        *(.text.tpx_particle_draw_tex_s8)
        *(.text.tpx_particle_draw_tex_s16)
        *(.text.tpx_matrix_set)
        *(.text.tpx_init)
        *(.text.tpx_matrix_push)
        *(.text.tpx_matrix_pop)
        *(.text.data_cache_hit_writeback_invalidate)
        *(.text.inst_cache_hit_invalidate)
        *(.text.malloc_uncached)
        *(.text.malloc_uncached_aligned)
        *(.text.free_uncached)
        *(.text.get_memory_size)
        *(.text.wait_ms)
        *(.text.die)
        *(.text.sys_get_version)
        *(.text.sys_hw_memset)
        *(.text.sys_hw_memset16)
        *(.text.sys_hw_memset32)
        *(.text.startup.__n64sys_hwmemset_emucheck)
        *(.text.__mi_memset)
        *(.text.__MI_BB_handler)
        *(.text.__CART_handler)
        *(.text.__RESET_handler)
        *(.text.register_AI_handler)
        *(.text.register_VI_handler)
        *(.text.register_PI_handler)
        *(.text.register_DP_handler)
        *(.text.register_SI_handler)
        *(.text.register_SP_handler)
        *(.text.register_TI_handler)
        *(.text.set_AI_interrupt)
        *(.text.set_VI_interrupt)
        *(.text.set_PI_interrupt)
        *(.text.set_DP_interrupt)
        *(.text.set_SI_interrupt)
        *(.text.set_SP_interrupt)
        *(.text.set_TI_interrupt)
        *(.text.startup.__init_interrupts)
        *(.text.get_interrupts_state)
        *(.text.reseed_from_entropy)
        *(.text.getentropy64)
        *(.text.getentropy32)
        *(.text.__xorshift64)
        *(.text.__rand64)
        *(.text.startup.__rand_init)
        *(.text.emux_write)
        *(.text.__stderr_write)
        *(.text.usblog_write)
        *(.text.isviewer_write)
        *(.text.debugfv)
        *(.text.debug_init_usblog)
        *(.text.debug_init_emulog)
        *(.text.debugf)
        *(.text.debug_assert_func_f)
        *(.text.debug_assert_func)
        *(.text.debug_hexdump)
        *(.text.__debug_backtrace)
        *(.text.debug_backtrace)
        *(.text._ZL13demangle_namePc)
        *(.text._ZL17terminate_handlerv)
        *(.text._Z16__debug_init_cppv)
        *(.text.usb_64drive_read)
        *(.text.usb_everdrive_read)
        *(.text.usb_sc64_read)
        *(.text.usb_64drive_poll)
        *(.text.usb_everdrive_usbbusy)
        *(.text.usb_everdrive_readusb)
        *(.text.usb_everdrive_poll)
        *(.text.usb_everdrive_write)
        *(.text.usb_sc64_poll)
        *(.text.usb_write)
        *(.text.usb_sendheartbeat)
        *(.text.usb_64drive_wait)
        *(.text.usb_64drive_write)
        *(.text.usb_sc64_execute_cmd)
        *(.text.usb_sc64_write)
        *(.text.rompak_get_header)
        *(.text.walkfn.0)
        *(.text.rompak_walk)
        *(.text.rompak_search_ext)
        *(.text.rompak_version_parse)
        *(.text.startup.__rompak_init)
        *(.text.get_next_token)
        *(.text.lookup_file)
        *(.text.__close)
        *(.text.__dfs_set_errno)
        *(.text.__fstat)
        *(.text.__ioctl)
        *(.text.find_dirent)
        *(.text.recurse_path)
        *(.text.__dfs_findnext)
        *(.text.__findnext)
        *(.text.__dfs_init)
        *(.text.__dfs_findfirst)
        *(.text.__findfirst)
        *(.text.__stat)
        *(.text.__lseek)
        *(.text.dfs_open)
        *(.text.__open)
        *(.text.dfs_read)
        *(.text.__read)
        *(.text.dfs_init)
        *(.text.audio_carve_buffers)
        *(.text.audio_init)
        *(.text.audio_set_buffer_granularity)
        *(.text.audio_get_frequency)
        *(.text.apply_display_vi_config.isra.0)
        *(.text.display_init)
        *(.text.display_close)
        *(.text.display_get_height)
        *(.text.tex_format_name)
        *(.text.surface_alloc)
        *(.text.surface_free)
        *(.text.seekfn_cmp)
        *(.text.closefn_none)
        *(.text.closefn_cmp)
        *(.text.readfn_cmp)
        *(.text.seekfn_none)
        *(.text.readfn_none)
        *(.text.must_open.part.0)
        *(.text.asset_read_header)
        *(.text.__asset_init_compression_lvl2)
        *(.text.must_open)
        *(.text.decompress_full)
        *(.text.asset_read)
        *(.text.asset_load)
        *(.text.asset_fdopen)
        *(.text.asset_fopen)
        *(.text.__clip_blit)
        *(.text.color_to_packed32)
        *(.text.graphics_set_color)
        *(.text.graphics_fill_screen)
        *(.text.graphics_set_default_font)
        *(.text.graphics_draw_character)
        *(.text.rsp_load_code)
        *(.text.rsp_load_data)
        *(.text.rsp_load)
        *(.text.rsp_read_code)
        *(.text.rsp_read_data)
        *(.text.__rsp_run_async)
        *(.text.__rsp_check_assert)
        *(.text.rsp_wait)
        *(.text.rsp_run)
        *(.text.is_wrap_break_char)
        *(.text.cb.3)
        *(.text.inspector_print_backtrace)
        *(.text.inspector_page_threads)
        *(.text.inspector_page_version)
        *(.text.inspector_page_fpr)
        *(.text.inspector_page_gpr)
        *(.text.version_walk)
        *(.text.inspector)
        *(.text.handler.4)
        *(.text.inspector_page_disasm)
        *(.text.inspector_page_exception)
        *(.text.__inspector_add_page)
        *(.text.__inspector_exception)
        *(.text.__inspector_assertion)
        *(.text.__inspector_cppexception)
        *(.text.startup.__inspector_init)
        *(.text.__sprite_ext)
        *(.text.sprite_get_lod_pixels.part.0)
        *(.text.__sprite_upgrade)
        *(.text.sprite_load_buf)
        *(.text.sprite_load)
        *(.text.sprite_free)
        *(.text.sprite_get_pixels)
        *(.text.sprite_get_lod_pixels)
        *(.text.sprite_get_detail_pixels)
        *(.text.sprite_get_palette)
        *(.text.sprite_get_palette_used_colors)
        *(.text.sprite_get_texparms)
        *(.text.sprite_fits_tmem)
        *(.text.sprite_is_shq)
        *(.text.pi_poll)
        *(.text.pi_interrupt)
        *(.text.pi_manual_interrupt_poll)
        *(.text.pi_enqueue)
        *(.text.dma_wait_and_disable_interrupts)
        *(.text.dma_read_raw_async)
        *(.text.dma_read_async)
        *(.text.dma_wait_started)
        *(.text.dma_wait_finished)
        *(.text.dma_read)
        *(.text.dma_write)
        *(.text.io_read)
        *(.text.io_write)
        *(.text.startup.__dma_init)
        *(.text.timer_init)
        *(.text.new_timer_context)
        *(.text.is_unmapped_kx64)
        *(.text.__get_exception_name.isra.0)
        *(.text.__exception_dump_header)
        *(.text.__exception_dump_gpr)
        *(.text.__exception_dump_fpr)
        *(.text.exception_default_handler)
        *(.text.__onCriticalException)
        *(.text.register_syscall_handler)
        *(.text.__onSyscallException)
        *(.text.__wrap___do_global_ctors)
        *(.text.inspector_page_modules)
        *(.text.startup.__dl_register_inspector)
        *(.text.kthread_free)
        *(.text.__thlist_add.part.0)
        *(.text.startup.__kernel_tls_init)
        *(.text.__kthread_check_overflow)
        *(.text.__thlist_splice_pri)
        *(.text.kmutex_unlock_internal)
        *(.text.__kthread_syscall_schedule)
        *(.text.kthread_current)
        *(.text.kthread_yield)
        *(.text.kthread_suspend)
        *(.text.kthread_backtrace)
        *(.text.kmutex_init)
        *(.text.kmutex_destroy)
        *(.text.kmutex_unlock)
        *(.text.__kcond_broadcast_isr)
        *(.text.kcond_wait)
        *(.text.kirq_begin_wait_si)
        *(.text.kirq_begin_wait_pi)
        *(.text.kirq_wait)
        *(.text.mixer_ramp_linear)
        *(.text.mixer_ch_bounds)
        *(.text.mixer_refresh_max_ns)
        *(.text.mixer_fold_volumes)
        *(.text.mixer_channel_window)
        *(.text.mixer_ramp_at)
        *(.text.mixer_ch_apply_freq)
        *(.text.mixer_vadpcm_seek)
        *(.text.mixer_large_loop_wrap)
        *(.text.mixer_ch_unpin_loop)
        *(.text.mixer_ramp_exp)
        *(.text.mixer_vadpcm_frame_bytes.part.0)
        *(.text.waveform_read)
        *(.text.mixer_calc_buffer_size)
        *(.text.mixer_wave_fits)
        *(.text.mixer_loop_fits)
        *(.text.mixer_ramp_to)
        *(.text.__mixer_inflight_samples)
        *(.text.mixer_set_vol)
        *(.text.mixer_ch_set_freq)
        *(.text.mixer_ch_set_vol)
        *(.text.mixer_ch_set_vol_ramp)
        *(.text.mixer_ch_set_gain)
        *(.text.mixer_ch_set_gain_ramp)
        *(.text.mixer_ch_stop)
        *(.text.mixer_ch_playing_waveform)
        *(.text.mixer_ch_playing)
        *(.text.mixer_ch_set_priority)
        *(.text.mixer_ch_set_limits)
        *(.text.mixer_init)
        *(.text.mixer_remove_event)
        *(.text.samplebuffer_copy)
        *(.text.samplebuffer_align_len.isra.0)
        *(.text.samplebuffer_recalc_size)
        *(.text.samplebuffer_dma_wait)
        *(.text.samplebuffer_init)
        *(.text.samplebuffer_set_unit_bytes)
        *(.text.samplebuffer_set_waveform)
        *(.text.samplebuffer_is_inited)
        *(.text.samplebuffer_close)
        *(.text.samplebuffer_prefetch)
        *(.text.samplebuffer_append)
        *(.text.samplebuffer_flush)
        *(.text.samplebuffer_get)
        *(.text.wav64_none_init)
        *(.text.wav64_none_get_bitrate)
        *(.text.wav64_none_read)
        *(.text.wav64_load)
        *(.text.wav64_play)
        *(.text.wav64_set_loop)
        *(.text.wav64_close)
        *(.text.wav64_vadpcm_find_skippoint)
        *(.text.huffv_decompress)
        *(.text.waveform_vadpcm_read)
        *(.text.wav64_vadpcm_preload)
        *(.text.wav64_vadpcm_init)
        *(.text.wav64_vadpcm_close)
        *(.text.wav64_vadpcm_get_bitrate)
        *(.text.wav64_vadpcm_adjust_seek)
        *(.text.joypad_gcn_origin_callback)
        *(.text.joybus_input_read_n64_controllers)
        *(.text.joypad_device_reset)
        *(.text.joypad_read_n64_inputs)
        *(.text.joypad_init)
        *(.text.rspq_sp_interrupt)
        *(.text.rspq_init_context.constprop.0)
        *(.text.rspq_chain_free.constprop.0)
        *(.text.rspq_crash_handler)
        *(.text.rspq_assert_handler)
        *(.text.rspq_chain_next.isra.0)
        *(.text.rspq_init)
        *(.text.rspq_block_begin_reuse)
        *(.text.rspq_block_end)
        *(.text.rspq_block_free)
        *(.text.rspq_syncpoint_new)
        *(.text.rspq_overlay_register_internal)
        *(.text.rspq_overlay_register)
        *(.text.rspq_overlay_unregister)
        *(.text.rspq_highpri_sync)
        *(.text.rspq_syncpoint_wait)
        *(.text.rspq_wait)
        *(.text.rspq_overlay_get_state)
        *(.text.rdpq_assert_handler)
        *(.text.rdpq_set_tile)
        *(.text.__rdpq_autosync_use)
        *(.text.rdpq_config_set)
        *(.text.rdpq_config_disable)
        *(.text.__rdpq_block_begin)
        *(.text.__rdpq_block_recycle)
        *(.text.__rdpq_block_next_buffer)
        *(.text.__rdpq_block_end)
        *(.text.__rdpq_block_run_maybe_rdp)
        *(.text.__rdpq_block_free)
        *(.text.__rdpq_block_reserve)
        *(.text.__rdpq_block_update)
        *(.text.rdpq_set_blend_color)
        *(.text.rdpq_set_env_color)
        *(.text.rdpq_set_prim_color)
        *(.text.__rdpq_write8_syncchangeuse)
        *(.text.rdpq_set_texture_image)
        *(.text.__rdpq_set_other_modes)
        *(.text.rdpq_init)
        *(.text.__rdpq_change_other_modes)
        *(.text.rdpq_set_tile_autotmem)
        *(.text.rdpq_sync_load)
        *(.text.rdpq_triangle_rsp)
        *(.text.rdpq_triangle)
        *(.text.__rdpq_texture_rectangle_scaled_offline)
        *(.text.rdpq_mode_blender)
        *(.text.rdpq_mode_alphacompare)
        *(.text.rdpq_mode_combiner)
        *(.text.sprite_upload_palette)
        *(.text.__rdpq_sprite_upload)
        *(.text.rdpq_sprite_upload)
        *(.text.rdpq_sprite_blit)
        *(.text.texload_set_rect)
        *(.text.tex_xblit_norotate_noscale)
        *(.text.tex_xblit_norotate)
        *(.text.tex_xblit_xform)
        *(.text.draw_cb.0)
        *(.text.draw_cb.1)
        *(.text.draw_cb.2)
        *(.text.tex_xblit)
        *(.text.draw_cb.3)
        *(.text.rdpq_load_block.part.0)
        *(.text.texload_tile)
        *(.text.texload_tile_4bpp)
        *(.text.texload_block_4bpp)
        *(.text.texload_block)
        *(.text.tex_loader_load)
        *(.text.ltd_texloader)
        *(.text.rdpq_tex_upload_sub)
        *(.text.rdpq_tex_upload)
        *(.text.rdpq_tex_reuse_sub)
        *(.text.rdpq_tex_reuse)
        *(.text.__rdpq_tex_blit)
        *(.text.rdpq_tex_upload_tlut)
        *(.text.rdpq_tex_multi_begin)
        *(.text.rdpq_tex_multi_end)
        *(.text.rdpq_attach.part.0)
        *(.text.__rdpq_font_glyph_sparse.isra.0)
        *(.text.rdpq_font_load)
        *(.text.rdpq_font_free)
        *(.text.__rdpq_font_kerning)
        *(.text.rdpq_font_style)
        *(.text.__rdpq_font_load_builtin_1)
        *(.text.rdpq_text_register_font)
        *(.text.rdpq_text_unregister_font)
        *(.text.char_compare)
        *(.text.paragraph_extend)
        *(.text.__rdpq_paragraph_builder_newline)
        *(.text.paragraph_wrap)
        *(.text.rdpq_paragraph_build)
        *(.text.rdpq_paragraph_free)
        *(.text.transform_point)
        *(.text.__rdpq_xform_init)
        *(.text.rdpq_xform_mtx_mult)
        *(.text.rdpq_xform_mult_srt)
        *(.text.rdpq_xform_push)
        *(.text.rdpq_xform_pop)
        *(.text.rdpq_xform_texture_rectangle)
        *(.text.fm_exp2f)
        *(.text.fm_mat3_from_srt)
        *(.text.decompress_lz4_full_inplace)
        *(.text.decompress_lz4_init)
        *(.text.decompress_lz4_reset)
        *(.text.decompress_lz4_full_fast)
        *(.text.__ringbuf_init)
        *(.text.__ringbuf_write)
        *(.text.__ringbuf_copy)
        *(.text.__lookahead_buf_refill)
        *(.text.__lookahead_buf_reset)
        *(.text.__lookahead_buf_init)
        *(.text.decompress_aplib_init)
        *(.text.decompress_aplib_reset)
        *(.text.decompress_aplib_read)
        *(.text.decompress_aplib_full_inplace)
        *(.text.shr_read_u32be)
        *(.text.decompress_shrinkler_full_inplace)
        *(.text.decompress_shrinkler_init)
        *(.text.decompress_shrinkler_reset)
        *(.text.__symbolize)
        *(.text.__bt_analyze_func)
        *(.text.backtrace)
        *(.text.__backtrace_from)
        *(.text.backtrace_symbols_cb)
        *(.text.backtrace_frame_print)
        *(.text.symt_get_string)
        *(.text.symt_open)
        *(.text.symt_find_symbol)
        *(.text.symt_get_func_name)
        *(.text.symt_get_file_name)
        *(.text.__utf8_decode)
        *(.text.__read_varint_u64)
        *(.text.__read_varint_s64)
        *(.text.__set_output)
        *(.text.vi_write_end_forced)
        *(.text.vi_set_interlaced)
        *(.text.vi_set_aa_mode)
        *(.text.vi_set_divot)
        *(.text.vi_set_dedither)
        *(.text.vi_set_gamma)
        *(.text.vi_set_output)
        *(.text.vi_set_borders)
        *(.text.vi_calc_borders)
        *(.text.vi_wait_vblank)
        *(.text.vi_install_vblank_handler)
        *(.text.vi_uninstall_vblank_handler)
        *(.text.vi_set_timing_preset)
        *(.text.vi_reset)
        *(.text.vi_init)
        *(.text.__console_render.part.0)
        *(.text.__console_write)
        *(.text.console_set_render_mode)
        *(.text.console_init)
        *(.text.console_render)
        *(.text.console_set_debug)
        *(.text.startup.__joybus_init)
        *(.text.joybus_exec)
        *(.text.joybus_register_detection_callback)
        *(.text.joybus_init)
        *(.text.decompress_aplib_full_fast)
        *(.text.decompress_shrinkler_full_fast)
        *(.text.__get_fs_link_by_name)
        *(.text.attach_filesystem)
        *(.text.close)
        *(.text.fstat)
        *(.text.getpid)
        *(.text.isatty)
        *(.text.kill)
        *(.text.lseek)
        *(.text.open)
        *(.text.read)
        *(.text.sbrk)
        *(.text.sbrk_top)
        *(.text.write)
        *(.text.hook_stdio_calls)
        *(.text._flush_cache)
        *(.text.__assert_func)
        *(.text.__retarget_lock_init_recursive)
        *(.text.__retarget_lock_close_recursive)
        *(.text.__cxa_begin_catch)
        *(.text.__cxa_end_catch)
        *(.text.__cxa_get_globals)
        *(.text._ZL16get_adjusted_ptrPKSt9type_infoS1_PPv)
        *(.text._ZL28read_encoded_value_with_basehjPKhPj)
        *(.text._ZL21base_of_encoded_valuehP15_Unwind_Context)
        *(.text._ZL17parse_lsda_headerP15_Unwind_ContextPKhP16lsda_header_info)
        *(.text._ZL20check_exception_specP16lsda_header_infoPKSt9type_infoPvl)
        *(.text.__gxx_personality_v0)
        *(.text._ZL33__gxx_dependent_exception_cleanup19_Unwind_Reason_CodeP17_Unwind_Exception)
        *(.text._ZNSt15__exception_ptr13exception_ptr9_M_addrefEv)
        *(.text._ZNSt15__exception_ptr13exception_ptr10_M_releaseEv)
        *(.text._ZSt17current_exceptionv)
        *(.text._ZSt17rethrow_exceptionNSt15__exception_ptr13exception_ptrE)
        *(.text._ZN10__cxxabiv111__terminateEPFvvE)
        *(.text.unlikely._ZSt9terminatev)
        *(.text._ZN10__cxxabiv112__unexpectedEPFvvE)
        *(.text.unlikely._ZSt10unexpectedv)
        *(.text._ZSt13set_terminatePFvvE)
        *(.text._ZSt13get_terminatev)
        *(.text.__cxa_rethrow)
        *(.text._ZN10__cxxabiv120__si_class_type_infoD2Ev)
        *(.text._ZN10__cxxabiv120__si_class_type_infoD0Ev)
        *(.text._ZNK10__cxxabiv120__si_class_type_info12__do_dyncastEiNS_17__class_type_info10__sub_kindEPKS1_PKvS4_S6_RNS1_16__dyncast_resultE)
        *(.text._ZNK10__cxxabiv120__si_class_type_info20__do_find_public_srcEiPKvPKNS_17__class_type_infoES2_)
        *(.text._ZNK10__cxxabiv120__si_class_type_info11__do_upcastEPKNS_17__class_type_infoEPKvRNS1_15__upcast_resultE)
        *(.text._ZN9__gnu_cxx27__verbose_terminate_handlerEv)
        *(.text._ZNK10__cxxabiv117__class_type_info11__do_upcastEPKS0_PPv)
        *(.text._ZNK10__cxxabiv117__class_type_info20__do_find_public_srcEiPKvPKS0_S2_)
        *(.text._ZN10__cxxabiv117__class_type_infoD2Ev)
        *(.text._ZN10__cxxabiv117__class_type_infoD0Ev)
        *(.text._ZNK10__cxxabiv117__class_type_info11__do_upcastEPKS0_PKvRNS0_15__upcast_resultE)
        *(.text._ZNK10__cxxabiv117__class_type_info10__do_catchEPKSt9type_infoPPvj)
        *(.text._ZNK10__cxxabiv117__class_type_info12__do_dyncastEiNS0_10__sub_kindEPKS0_PKvS3_S5_RNS0_16__dyncast_resultE)
        *(.text._ZdlPvj)
        *(.text._ZN12_GLOBAL__N_14pool4freeEPv.constprop.0)
        *(.text._ZN12_GLOBAL__N_14pool8allocateEj.constprop.0)
        *(.text.__cxa_free_exception)
        *(.text.__cxa_allocate_dependent_exception)
        *(.text.__cxa_free_dependent_exception)
        *(.text.startup._GLOBAL__sub_I__ZN9__gnu_cxx9__freeresEv)
        *(.text.unlikely.__cxa_call_terminate)
        *(.text.__cxa_current_exception_type)
        *(.text._ZdlPv)
        *(.text.*)
        KEEP(*(keep.text.*))
        *(.init)
        *(.fini)
        *(.gnu.linkonce.t.*)
        . = ALIGN(16);
        __text_end  = .;
    } :main

   .eh_frame_hdr : { *(.eh_frame_hdr) }
   .eh_frame : { 
        __EH_FRAME_BEGIN__ = .; /* Define symbol for accessing eh_frame section */
        KEEP (*(.eh_frame)) 
    }
   .gcc_except_table : { *(.gcc_except_table*) } 
   .jcr : { KEEP (*(.jcr)) } 

    .rodata : {
        *(.rdata)
        *(.rodata)
        *(.rodata.*)
        KEEP(*(keep.rodata.*))
        *(.gnu.linkonce.r.*)
        . = ALIGN(4);
        __tdata_align = .;
        LONG (ALIGNOF(.tdata));
        . = ALIGN(8);
    }

    /* This is important to keep __CTOR_END__ consistent */
    . = ALIGN(4);

    .ctors : {
        __CTOR_LIST__ = .;
        /* Actually we should place the count here like;

        LONG((__CTOR_END__ - __CTOR_LIST__) / 4 - 2)

        but g++ seem to already do this (though incorrectly placing an 0xFFFFFFFF)
        and that breaks things if we also add it. Ideally this should be parsed
        by the code but we already know the end as well.

        The new build system links everything via g++ by default and should use
        __wrap___do_global_ctors and enables it via the --wrap linker option.
        When linking with ld, we should use __do_global_ctors, which is the default
        if you don't provide the --wrap option. */
        KEEP(*(EXCLUDE_FILE (*crtend.o) .ctors))
        KEEP(*(SORT(.ctors.*)))
        KEEP(*crtend.o(.ctors))
         /* Similarly we should have a;

        LONG(0)

        here, and g++ seem to insert it at __CTOR_END__ */
        __CTOR_END__ = .;
    }

    . = ALIGN(8);

    /* Data section has relocation address at start of RAM in cached,
    * unmapped memory, but is loaded just at the end of the text segment,
    * and must be copied to the correct location at startup
    * Gather all initialised data together.  The memory layout
    * will place the global initialised data at the lowest addrs.
    * The lit8, lit4, sdata and sbss sections have to be placed
    * together in that order from low to high addrs with the _gp symbol
    * positioned (aligned) at the start of the sdata section.
    * We then finish off with the standard bss section
    */
    .data : {
        __data_start = .;
        *(.data)
        *(.data.*)
        KEEP(*(keep.data.*))
        *(.gnu.linkonce.d.*)
        . = ALIGN(8);
    }
    
    .tdata : {
        __tls_base = .;
        __tdata_start = .;
        *(.tdata)
        *(.tdata.*)
        *(.gnu.linkonce.td.*)
        __tdata_end = .;
    }
    
    .tbss : {
        __tbss_start = .;
        *(.tbss)
        *(.tbss.*)
        *(.gnu.linkonce.tb.*)
        . = ALIGN(8);
        __tbss_end = .;
        __tls_end = .;
    }
    
    /* Fix dot for TBSS Sections */
    . = .+(__tbss_end-__tbss_start);
    
    /* Small data START */

    .sdata : {
        _gp = . + 0x8000;
        *(.sdata)
        *(.sdata.*)
        *(.gnu.linkonce.s.*)
        . = ALIGN(8);
    }

    .lit8 : {
        *(.lit8)
        . = ALIGN(8);
    }
    .lit4 : {
        *(.lit4)
        . = ALIGN(8);
    }

    . = ALIGN(8);
    __data_end = .;

    /* Here the ROM is finished. The rest is just in RAM */
    . = ALIGN(8);
    __rom_end = .;

    .sbss : {
         __bss_start = .;
        *(.sbss)
        *(.sbss.*)
        *(.gnu.linkonce.sb.*)
        *(.scommon)
        *(.scommon.*)
    }

    /* Small data END */

    . = ALIGN(8);
    .bss : {
        *(.bss)
        *(.bss*)
        *(.gnu.linkonce.b.*)
        *(COMMON)
        . = ALIGN(8);
        __th_tdata_copy = .;
        . = .+(__tdata_end-__tdata_start);
        . = ALIGN(8);
         __bss_end = .;
    }

    . = ALIGN(8);

    /* Deprecated */
    end = .;
}

/* Give an assert for a too huge binary. The maximum allowed size here is 8 MiB,
   minus the space for the stack and the initial low memory section. 
   Notice the exact size doesn't matter much: we want to detect mistakes that
   would be much harder to find at runtime when no heap is available... */
ASSERT(end - __text_start <= 8*1024*1024 - 64*1024 - 1024, "ERROR: the generated ELF is too big for N64 memory")
